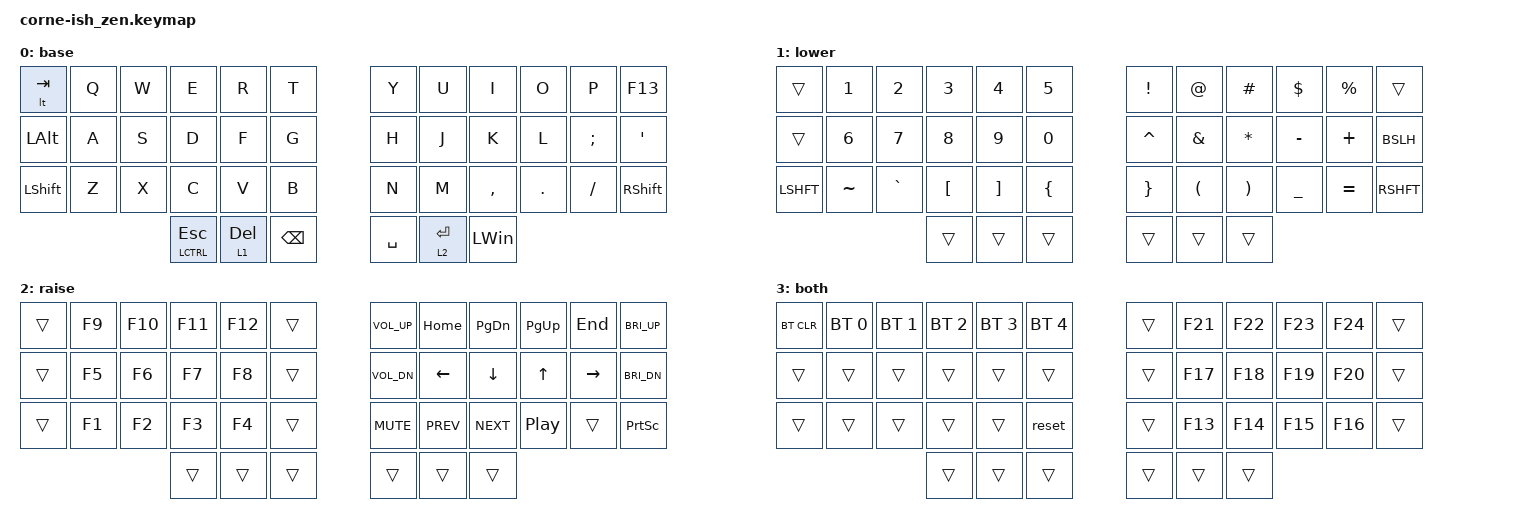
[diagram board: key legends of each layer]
#define BASE 0
#define LWR 1
#define RSE 2
#define BOTH 3

//  0  1  2  3  4  5     6  7  8  9 10 11
// 12 13 14 15 16 17    18 19 20 21 22 23
// 24 25 26 27 28 29    30 31 32 33 34 35
//          36 37 38    39 40 41
#define LEFT_HAND <0 1 2 3 4 5 12 13 14 15 16 17 24 25 26 27 28 29>
#define RIGHT_HAND <6 7 8 9 10 11 18 19 20 21 22 23 30 31 32 33 34 35>

#include <behaviors.dtsi>
#include <dt-bindings/zmk/bt.h>
#include <dt-bindings/zmk/keys.h>


/ {
    behaviors {
        hm: homerow_mods {
            compatible = "zmk,behavior-hold-tap";
            label = "HOMEROW_MODS";
            #binding-cells = <2>;
            tapping-term-ms = <200>;
            quick_tap_ms = <125>;
            global-quick-tap;
            flavor = "tap-preferred";
            bindings = <&kp>, <&kp>;
        };
    };

    // combos {
    //     compatible = "zmk,combos";

    //     capsword {
    //         bindings = <&caps_word>;
    //         key-positions = <16 15>;
    //     };
    // };

    macros {
        hyper: hyper {
            compatible = "zmk,behavior-macro";
            #binding-cells = <0>;
            bindings = <&kp LSHFT &kp LCTRL &kp LEFT_ALT &kp LEFT_WIN>;
            label = "HYPER";
        };

        meh: meh {
            compatible = "zmk,behavior-macro";
            #binding-cells = <0>;
            bindings = <&kp LSHFT &kp LCTRL &kp LEFT_ALT>;
            label = "MEH";
        };
    };

    conditional_layers {
        compatible = "zmk,conditional-layers";

        third_layer {
            if-layers = <1 2>;
            then-layer = <3>;
        };
    };

    keymap {
        compatible = "zmk,keymap";

        base {
            bindings = <
&lt TAB          &kp Q           &kp W              &kp E              &kp R           &kp T                       &kp Y         &kp U             &kp I              &kp O             &kp P              &kp F13
&kp LALT         &kp A           &kp S              &kp D              &kp F           &kp G                       &kp H         &kp J             &kp K              &kp L             &kp SEMI           &kp APOS
&kp LSHFT        &kp Z           &kp X              &kp C              &kp V           &kp B                       &kp N         &kp M             &kp COMMA          &kp DOT           &kp FSLH           &kp RSHFT
                                                    &lt LCTRL ESC      &lt 1 DELETE    &kp BACKSPACE               &kp SPACE     &lt 2 RETURN      &kp LWIN
            >;
        };

        lower {
            bindings = <
&trans  &kp N1     &kp N2     &kp N3    &kp N4    &kp N5                        &kp EXCLAMATION  &kp AT_SIGN    &kp POUND     &kp DOLLAR  &kp PERCENT  &trans
&trans  &kp N6     &kp N7     &kp N8    &kp N9    &kp N0                        &kp CARET        &kp AMPERSAND  &kp ASTERISK  &kp MINUS   &kp PLUS     &BSLH
&LSHFT  &kp TILDE  &kp GRAVE  &kp LBKT  &kp RBKT  &kp LEFT_BRACE                &kp RIGHT_BRACE  &kp LPAR       &kp RPAR      &kp UNDER   &kp EQUAL    &RSHFT
                              &trans    &trans    &trans                        &trans           &trans         &trans
            >;
        };

        raise {
            bindings = <
&trans  &kp F9  &kp F10  &kp F11  &kp F12  &trans                &kp C_VOL_UP  &kp HOME    &kp PG_DN   &kp PG_UP         &kp END    &kp C_BRI_UP
&trans  &kp F5  &kp F6   &kp F7   &kp F8   &trans                &kp C_VOL_DN  &kp LEFT    &kp DOWN    &kp UP            &kp RIGHT  &kp C_BRI_DN
&trans  &kp F1  &kp F2   &kp F3   &kp F4   &trans                &kp C_MUTE    &kp C_PREV  &kp C_NEXT  &kp C_PLAY_PAUSE  &trans     &kp PRINTSCREEN
                         &trans   &trans   &trans                &trans        &trans      &trans
            >;
        };

        both {
            bindings = <
&bt BT_CLR  &bt BT_SEL 0  &bt BT_SEL 1  &bt BT_SEL 2  &bt BT_SEL 3  &bt BT_SEL 4                    &trans  &kp F21  &kp F22  &kp F23  &kp F24  &trans
&trans      &trans        &trans        &trans        &trans        &trans                          &trans  &kp F17  &kp F18  &kp F19  &kp F20  &trans
&trans      &trans        &trans        &trans        &trans        &reset                          &trans  &kp F13  &kp F14  &kp F15  &kp F16  &trans
                                        &trans        &trans        &trans                          &trans  &trans   &trans
            >;
        };
    };
};
